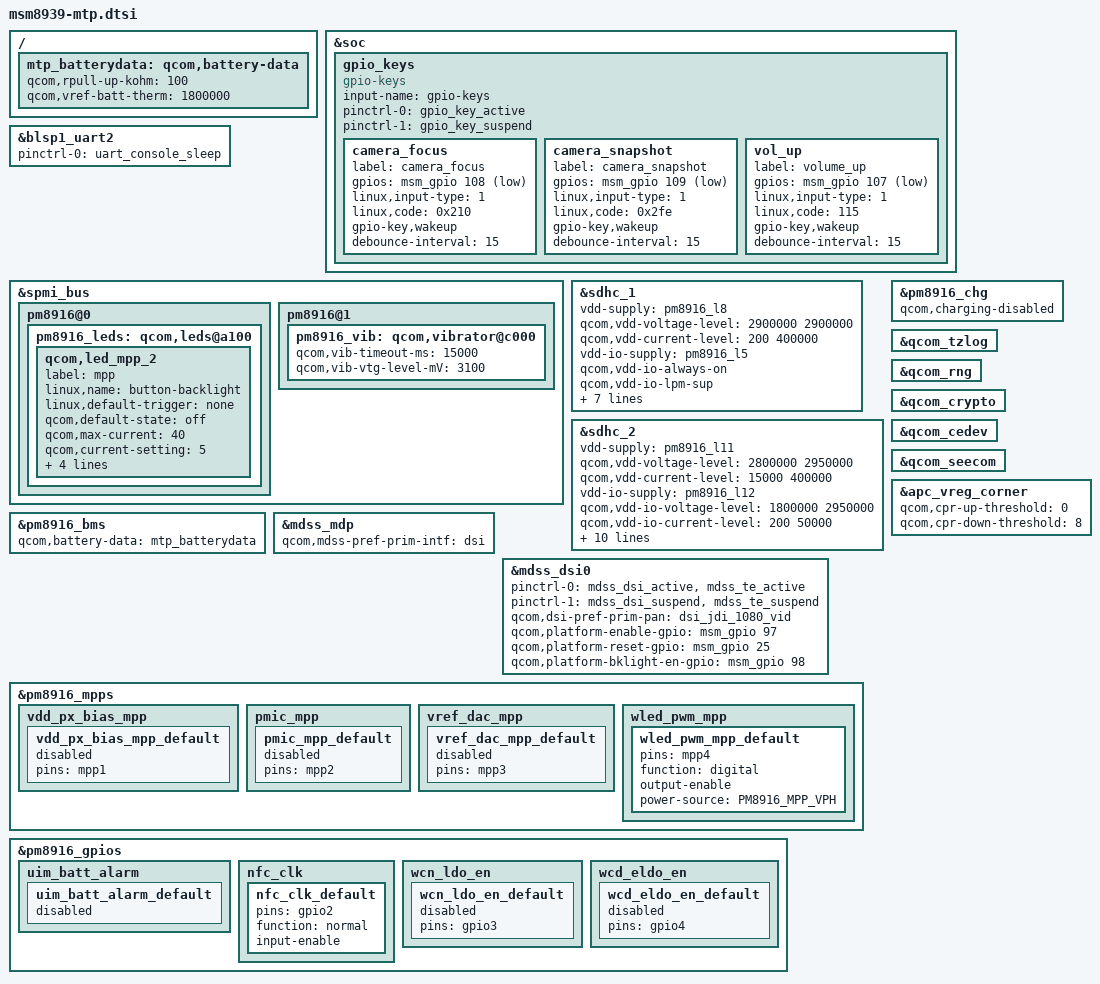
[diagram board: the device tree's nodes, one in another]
/* Copyright (c) 2014-2015, 2018, The Linux Foundation. All rights reserved.
 *
 * This program is free software; you can redistribute it and/or modify
 * it under the terms of the GNU General Public License version 2 and
 * only version 2 as published by the Free Software Foundation.
 *
 * This program is distributed in the hope that it will be useful,
 * but WITHOUT ANY WARRANTY; without even the implied warranty of
 * MERCHANTABILITY or FITNESS FOR A PARTICULAR PURPOSE.  See the
 * GNU General Public License for more details.
 */

#include <dt-bindings/pinctrl/qcom,pmic-mpp.h>
#include "msm8939-pinctrl.dtsi"
//#include "msm8939-camera-sensor-mtp.dtsi"

&soc {
	gpio_keys {
		compatible = "gpio-keys";
		input-name = "gpio-keys";
		pinctrl-names = "tlmm_gpio_key_active","tlmm_gpio_key_suspend";
		pinctrl-0 = <&gpio_key_active>;
		pinctrl-1 = <&gpio_key_suspend>;

		camera_focus {
			label = "camera_focus";
			gpios = <&msm_gpio 108 0x1>;
			linux,input-type = <1>;
			linux,code = <0x210>;
			gpio-key,wakeup;
			debounce-interval = <15>;
		};

		camera_snapshot {
			label = "camera_snapshot";
			gpios = <&msm_gpio 109 0x1>;
			linux,input-type = <1>;
			linux,code = <0x2fe>;
			gpio-key,wakeup;
			debounce-interval = <15>;
		};

		vol_up {
			label = "volume_up";
			gpios = <&msm_gpio 107 0x1>;
			linux,input-type = <1>;
			linux,code = <115>;
			gpio-key,wakeup;
			debounce-interval = <15>;
		};
	};
};

&blsp1_uart2 {
	status = "ok";
	pinctrl-names = "sleep";
	pinctrl-0 = <&uart_console_sleep>;
};

&spmi_bus {
	pm8916@0 {
		pm8916_leds: qcom,leds@a100 {
			status = "okay";
			qcom,led_mpp_2 {
				label = "mpp";
				linux,name = "button-backlight";
				linux,default-trigger = "none";
				qcom,default-state = "off";
				qcom,max-current = <40>;
				qcom,current-setting = <5>;
				qcom,id = <6>;
				qcom,mode = "manual";
				qcom,source-sel = <1>;
				qcom,mode-ctrl = <0x60>;
			};
		};
	};

	pm8916@1 {
		pm8916_vib: qcom,vibrator@c000 {
			qcom,vib-timeout-ms = <15000>;
			qcom,vib-vtg-level-mV = <3100>;
			status = "okay";
		};
	};
};

&sdhc_1 {
	vdd-supply = <&pm8916_l8>;
	qcom,vdd-voltage-level = <2900000 2900000>;
	qcom,vdd-current-level = <200 400000>;

	vdd-io-supply = <&pm8916_l5>;
	qcom,vdd-io-always-on;
	qcom,vdd-io-lpm-sup;
	qcom,vdd-io-voltage-level = <1800000 1800000>;
	qcom,vdd-io-current-level = <200 60000>;

	pinctrl-names = "active", "sleep";
	pinctrl-0 = <&sdc1_clk_on &sdc1_cmd_on &sdc1_data_on>;
	pinctrl-1 = <&sdc1_clk_off &sdc1_cmd_off &sdc1_data_off>;

	qcom,nonremovable;

	status = "ok";
};

&sdhc_2 {
	vdd-supply = <&pm8916_l11>;
	qcom,vdd-voltage-level = <2800000 2950000>;
	qcom,vdd-current-level = <15000 400000>;

	vdd-io-supply = <&pm8916_l12>;
	qcom,vdd-io-voltage-level = <1800000 2950000>;
	qcom,vdd-io-current-level = <200 50000>;

	pinctrl-names = "active", "sleep";
	pinctrl-0 = <&sdc2_clk_on &sdc2_cmd_on &sdc2_data_on &sdc2_cd_on>;
	pinctrl-1 = <&sdc2_clk_off &sdc2_cmd_off &sdc2_data_off &sdc2_cd_off>;

	#address-cells = <0>;
	interrupt-parent = <&sdhc_2>;
	interrupts = <0 1 2>;
	#interrupt-cells = <1>;
	interrupt-map-mask = <0xffffffff>;
	interrupt-map = <0 &intc 0 125 0
			1 &intc 0 221 0
			2 &msm_gpio 38 0>;
	interrupt-names = "hc_irq", "pwr_irq", "status_irq";
	cd-gpios = <&msm_gpio 38 0x1>;

	status = "ok";
};

&pm8916_chg {
	status = "ok";
	qcom,charging-disabled;
};

/ {
	mtp_batterydata: qcom,battery-data {
		qcom,rpull-up-kohm = <100>;
		qcom,vref-batt-therm = <1800000>;

		#include "batterydata-palladium.dtsi"
	};
};

&pm8916_bms {
	status = "ok";
	qcom,battery-data = <&mtp_batterydata>;
};

&qcom_tzlog {
	status = "okay";
};

&qcom_rng {
	status = "okay";
};

&qcom_crypto {
	status = "okay";
};

&qcom_cedev {
	status = "okay";
};

&qcom_seecom {
	status = "okay";
};

&mdss_mdp {
	qcom,mdss-pref-prim-intf = "dsi";
};

&mdss_dsi0 {
	pinctrl-names = "mdss_default", "mdss_sleep";
	pinctrl-0 = <&mdss_dsi_active &mdss_te_active>;
	pinctrl-1 = <&mdss_dsi_suspend &mdss_te_suspend>;
	qcom,dsi-pref-prim-pan = <&dsi_jdi_1080_vid>;

	qcom,platform-enable-gpio = <&msm_gpio 97 0>;
	qcom,platform-reset-gpio = <&msm_gpio 25 0>;
	qcom,platform-bklight-en-gpio = <&msm_gpio 98 0>;
};

&pm8916_mpps {
	/* VDD_PX_BIAS_MPP_1 */
	vdd_px_bias_mpp {
		vdd_px_bias_mpp_default: vdd_px_bias_mpp_default {
			pins = "mpp1";
			status = "disabled";
		};
	};

	/* PMIC_MPP_2 */
	pmic_mpp {
		pmic_mpp_default: pmic_mpp_default {
			pins = "mpp2";
			status = "disabled";
		};
	};

	/* VREF_DAC_MPP_3 */
	vref_dac_mpp {
		vref_dac_mpp_default: vref_dac_mpp_default {
			pins = "mpp3";
			status = "disabled";
		};
	};

	/* WLED_PWM_MPP_4 */
	wled_pwm_mpp {
		wled_pwm_mpp_default: wled_pwm_mpp_default {
			pins = "mpp4";
			function = "digital";
			output-enable;
			power-source = <PM8916_MPP_VPH>;
			status = "okay";
		};
	};

};

/* pm8916 gpio pinctrl configuration */
&pm8916_gpios {
	/* Battery UICC Alarm */
	uim_batt_alarm { /* GPIO 1 */
		uim_batt_alarm_default: uim_batt_alarm_default {
			status = "disabled";
		};
	};

	/* NFC_CLK_REQ */
	nfc_clk { /* GPIO 2 */
		nfc_clk_default: nfc_clk_default {
			pins = "gpio2";
			function = "normal";
			input-enable;
		};
	};

	/* External regulator control for WTR */
	wcn_ldo_en { /* GPIO 3 */
		wcn_ldo_en_default: wcn_ldo_en_default {
			pins = "gpio3";
			status = "disabled";
		};
	};

	/* External regulator control for APC */
	wcd_eldo_en { /* GPIO 4 */
		wcd_eldo_en_default: wcd_eldo_en_default {
			pins = "gpio4";
			status = "disabled";
		};
	};
};

&apc_vreg_corner {
		qcom,cpr-up-threshold = <0>;
		qcom,cpr-down-threshold = <8>;
};
